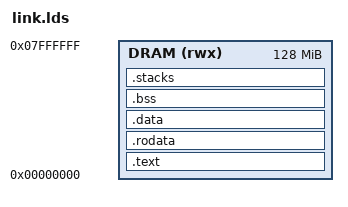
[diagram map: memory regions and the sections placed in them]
/***************************************************************************
 * Copyright (c) 2026 Eclipse ThreadX contributors
 *
 * This program and the accompanying materials are made available under the
 * terms of the MIT License which is available at
 * https://opensource.org/licenses/MIT.
 *
 * AI Disclosure: This file was largely AI-generated by Claude Code (Opus 5).
 * The AI-generated portions may be considered public domain (CC0-1.0)
 * and not subject to the project's licence. The human contributor has
 * reviewed and verified that the code is correct.
 *
 * SPDX-License-Identifier: MIT and CC0-1.0
 **************************************************************************/

/* Linker script for Cortex-R52 on the Armv8-R AEM FVP (BaseR platform).
 *
 * The BaseR memory map is the Base platform map with its two 2 GB halves
 * swapped: Base DRAM at 0x80000000 appears at 0x00000000 here, and the
 * 0x80000000-0xFFFFFFFF half holds peripherals and is NOT executable by
 * default.  Code must therefore be linked into low DRAM -- linking at
 * 0x80000000 produces a silent fault loop with no output.
 */

ENTRY(_start)

__hyp_stack_size__ = 0x0800;
__svc_stack_size__ = 0x1000;
__irq_stack_size__ = 0x0800;
__fiq_stack_size__ = 0x0400;
__abt_stack_size__ = 0x0400;
__und_stack_size__ = 0x0400;
__sys_stack_size__ = 0x0800;

MEMORY
{
    DRAM (rwx) : ORIGIN = 0x00000000, LENGTH = 0x08000000    /* 128 MB */
}

SECTIONS
{
    /* PMSAv8-R regions have a 64-byte granule and their limits are inclusive,
       so the code and data areas are separated on a 64-byte boundary.  Without
       this a single region would have to span both, forcing writable code or
       executable data.  */

    . = ALIGN(64);
    __code_start__ = .;

    .text :
    {
        KEEP(*(.vectors_el2))
        KEEP(*(.vectors_el1))
        *(.text*)
        *(.glue_7)
        *(.glue_7t)
    } > DRAM

    .rodata :
    {
        . = ALIGN(4);
        *(.rodata*)
        . = ALIGN(4);
    } > DRAM

    /* Start the writable area on a protection-region granule.
     *
     * The alignment belongs on the output section itself.  Two things that
     * look equivalent do not work: an assignment such as ". = ALIGN(64);"
     * between sections does not advance a MEMORY region's allocation
     * pointer, and ". = ALIGN(64);" at the end of .rodata does not extend
     * that section when no data follows it.  In both cases .data keeps its
     * unaligned address while __data_start__ reports the aligned one, so the
     * first bytes of .data fall inside the read-only code region.  The MPU
     * caught precisely that: writes to the two variables at the start of
     * .data faulted, and since one of them is the flag the abort handler
     * consults, the fault turned itself fatal.
     */

    .data ALIGN(64) :
    {
        __code_end__ = .;       /* code region ends where writable data begins */
        __data_start__ = .;
        *(.data*)
        . = ALIGN(4);
    } > DRAM

    .bss (NOLOAD) :
    {
        . = ALIGN(4);
        __bss_start__ = .;
        *(.bss*)
        *(COMMON)
        . = ALIGN(4);
        __bss_end__ = .;
    } > DRAM

    /* One stack per AArch32 processor mode.  SP must stay 8-byte aligned
       (AAPCS), so each region is aligned before its top symbol is taken.  */

    .stacks (NOLOAD) :
    {
        . = ALIGN(8);
        . = . + __hyp_stack_size__;
        __hyp_stack_top = .;

        . = ALIGN(8);
        . = . + __svc_stack_size__;
        __svc_stack_top = .;

        . = ALIGN(8);
        . = . + __irq_stack_size__;
        __irq_stack_top = .;

        . = ALIGN(8);
        . = . + __fiq_stack_size__;
        __fiq_stack_top = .;

        . = ALIGN(8);
        . = . + __abt_stack_size__;
        __abt_stack_top = .;

        . = ALIGN(8);
        . = . + __und_stack_size__;
        __und_stack_top = .;

        . = ALIGN(8);
        . = . + __sys_stack_size__;
        __sys_stack_top = .;
    } > DRAM

    . = ALIGN(8);
    _end = .;
    PROVIDE(end = .);

    /* Writable area for the MPU: data, bss, stacks and the heap that
       tx_application_define carves out of everything above _end.  */

    . = ALIGN(64);
    __data_end__ = . + 0x00100000;      /* 1 MB of heap beyond the image */
}
